# VPAC0_PAR_VPAC_VISS0_S_VBUSP_VISS_FCP_CFA_VBUSP_FLEXCFA register map
Vendor: Texas Instruments
Peripheral module from a debugger description file (folder J7ES).
Registers are 32-bit, read-write, reset 0x0 unless marked. A register's access mark holds for its fields unless they carry their own. Offsets are as the file gives them; lines under a group give offsets from that group; [hi:lo] are bit positions; {n}, {i} and the like mark numbered series; 'fields as' and 'values as' point back to an identical list; <NAME> marks a mode.

## VPAC0_PAR_VPAC_VISS0_S_VBUSP_VISS_FCP_CFA_VBUSP_FLEXCFA
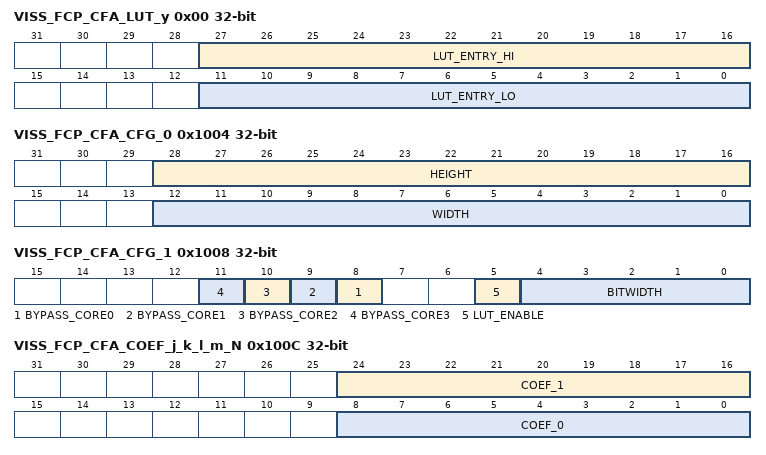
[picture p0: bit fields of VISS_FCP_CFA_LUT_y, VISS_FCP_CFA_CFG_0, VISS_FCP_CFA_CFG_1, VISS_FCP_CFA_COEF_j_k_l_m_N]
0x00 VISS_FCP_CFA_LUT_y — The LUT table contains the information used to reduce the pixle width to 12 from 13-16 Offset = 00088000h + (y * 4h); where y = 0h to 13Fh
  [27:16] LUT_ENTRY_HI — The upper LUT entry n+1.
  [11:0] LUT_ENTRY_LO — The lower LUT entry n+0.
0x1004 VISS_FCP_CFA_CFG_0 — The Control Register controls the input width and height of the module.
  [28:16] HEIGHT — Height of the input image
  [12:0] WIDTH — Width of the input image
0x1008 VISS_FCP_CFA_CFG_1 — The Control Register identifies the bit width of the input image
  [n+8] BYPASS_CORE{n} (n=0..3) — Setting the ~ibypass_core{n} bit will bypass filtering operation, output = input
  [5] LUT_ENABLE
  [4:0] BITWIDTH — BitWidth of the input image, values greater than 16 will be treated as 16 and values less than 12 will be treated as 12.
0x100C VISS_FCP_CFA_COEF_j_k_l_m_N — Coefficients for a=core, b=dir, c=phase, d=row, column=e*2+1 and e*2 Offset = 0008900Ch + (j * 360h) + (k * 120h) + (l * 48h) + (m * Ch) + (n * 4h); where j = 0h to 3h, k = 0h to 2h, l = 0h to 3h, m = 0h to 5h, n = 0h to 2h
  [24:16] COEF_1 — Coefficient - e*2+1
  [8:0] COEF_0 — Coefficient - e*2
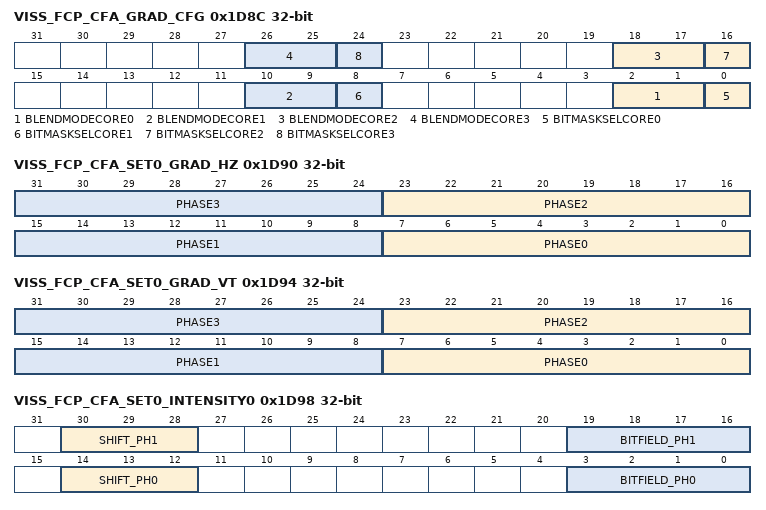
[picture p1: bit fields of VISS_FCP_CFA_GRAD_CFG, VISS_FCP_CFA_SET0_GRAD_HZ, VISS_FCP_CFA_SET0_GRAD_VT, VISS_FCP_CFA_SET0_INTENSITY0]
0x1D8C VISS_FCP_CFA_GRAD_CFG — Gradient configuration for all 4 cores
  [8n+2:8n+1] BLENDMODECORE{n} (n=0..3) — Core-{n} Blend (
  [8n] BITMASKSELCORE{n} (n=0..3) — Core-{n} Bitmask Select (
0x1D90 VISS_FCP_CFA_SET0_GRAD_HZ — Gradient Bitfield selector, Set-0 for Horizontal
  [8n+7:8n] PHASE{n} (n=0..3) — Bitfield selector for Phase-{n}
0x1D94 VISS_FCP_CFA_SET0_GRAD_VT — Gradient Bitfield selector, Set-0 for Vertical
  [8n+7:8n] PHASE{n} (n=0..3) — Bitfield selector for Phase-{n}
0x1D98 VISS_FCP_CFA_SET0_INTENSITY0 — Intensity Bitfield selector and shift for phase0/1
  [30:28] SHIFT_PH1 — Intensity shift for Phase-1
  [19:16] BITFIELD_PH1 — Intensity Bitfield selector for Phase-1
  [14:12] SHIFT_PH0 — Intensity shift for Phase-0
  [3:0] BITFIELD_PH0 — Intensity Bitfield selector for Phase-0
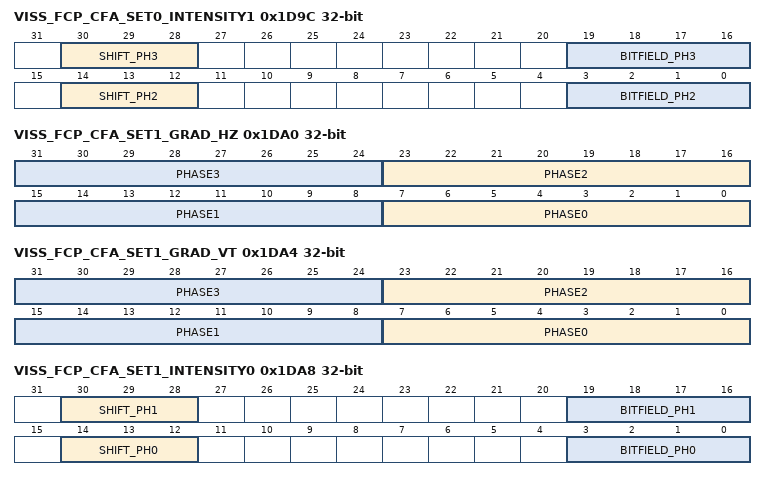
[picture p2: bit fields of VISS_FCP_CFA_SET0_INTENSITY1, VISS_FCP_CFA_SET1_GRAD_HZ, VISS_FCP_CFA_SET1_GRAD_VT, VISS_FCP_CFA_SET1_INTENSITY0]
0x1D9C VISS_FCP_CFA_SET0_INTENSITY1 — Intensity Bitfield selector and shift for phase2/3
  [30:28] SHIFT_PH3 — Intensity shift for Phase-3
  [19:16] BITFIELD_PH3 — Intensity Bitfield selector for Phase-3
  [14:12] SHIFT_PH2 — Intensity shift for Phase-2
  [3:0] BITFIELD_PH2 — Intensity Bitfield selector for Phase-2
0x1DA0 VISS_FCP_CFA_SET1_GRAD_HZ — Gradient Bitfield selector, Set-1 for Horizontal
  [8n+7:8n] PHASE{n} (n=0..3) — Bitfield selector for Phase-{n}
0x1DA4 VISS_FCP_CFA_SET1_GRAD_VT — Gradient Bitfield selector, Set-1 for Vertical
  [8n+7:8n] PHASE{n} (n=0..3) — Bitfield selector for Phase-{n}
0x1DA8 VISS_FCP_CFA_SET1_INTENSITY0 — Intensity Bitfield selector and shift for phase0/1
  fields as VISS_FCP_CFA_SET0_INTENSITY0
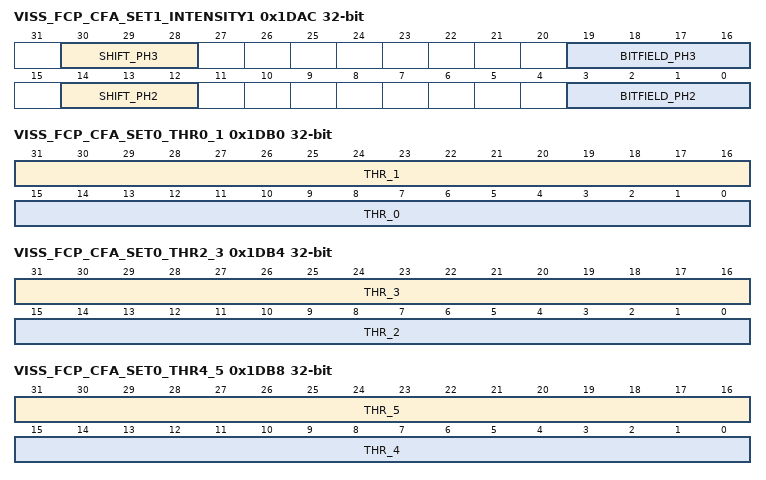
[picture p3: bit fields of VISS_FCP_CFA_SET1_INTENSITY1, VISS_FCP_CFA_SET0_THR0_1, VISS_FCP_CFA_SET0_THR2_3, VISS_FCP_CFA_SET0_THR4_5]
0x1DAC VISS_FCP_CFA_SET1_INTENSITY1 — Intensity Bitfield selector and shift for phase2/3
  fields as VISS_FCP_CFA_SET0_INTENSITY1
0x1DB0 VISS_FCP_CFA_SET0_THR0_1 — Set0 Thr0_1 for H/V Grad difference
  [31:16] THR_1 — H/V Grad diff Threshold_1
  [15:0] THR_0 — H/V Grad diff Threshold_0
0x1DB4 VISS_FCP_CFA_SET0_THR2_3 — Set0 Thr2_3 for H/V Grad difference
  [31:16] THR_3 — H/V Grad diff Threshold_3
  [15:0] THR_2 — H/V Grad diff Threshold_2
0x1DB8 VISS_FCP_CFA_SET0_THR4_5 — Set0 Thr4_5 for H/V Grad difference
  [31:16] THR_5 — H/V Grad diff Threshold_5
  [15:0] THR_4 — H/V Grad diff Threshold_4
0x1DBC VISS_FCP_CFA_SET0_THR6 — Set0 Thr6 for H/V Grad difference
  [15:0] THR_6 — H/V Grad diff Threshold_6
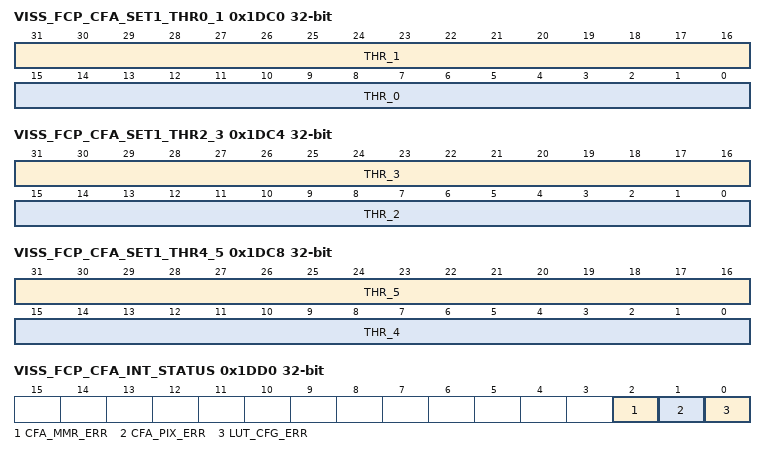
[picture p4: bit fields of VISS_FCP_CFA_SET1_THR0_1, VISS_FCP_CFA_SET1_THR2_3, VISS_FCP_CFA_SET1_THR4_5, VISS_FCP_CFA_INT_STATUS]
0x1DC0 VISS_FCP_CFA_SET1_THR0_1 — Set1 Thr0_1 for H/V Grad difference
  fields as VISS_FCP_CFA_SET0_THR0_1
0x1DC4 VISS_FCP_CFA_SET1_THR2_3 — Set1 Thr2_3 for H/V Grad difference
  fields as VISS_FCP_CFA_SET0_THR2_3
0x1DC8 VISS_FCP_CFA_SET1_THR4_5 — Set1 Thr4_5 for H/V Grad difference
  fields as VISS_FCP_CFA_SET0_THR4_5
0x1DCC VISS_FCP_CFA_SET1_THR6 — Set1 Thr6 for H/V Grad difference
  [15:0] THR_6 — H/V Grad diff Threshold_6
0x1DD0 VISS_FCP_CFA_INT_STATUS access not given — Status/clear register for flexcfa interrupts
  [2] CFA_MMR_ERR — status/clear for error writes to the FIR Filter MMRs during active frame causing potential frame corruption. (access RW1C)
  [1] CFA_PIX_ERR — status/clear for error on line array, set when software accesses pixel array during active frame causing potential frame corruption. (access RW1C)
  [0] LUT_CFG_ERR — status/clear for error on LUT cfg, set when software accesses LUT during active frame causing potential frame corruption. (access RW1C)
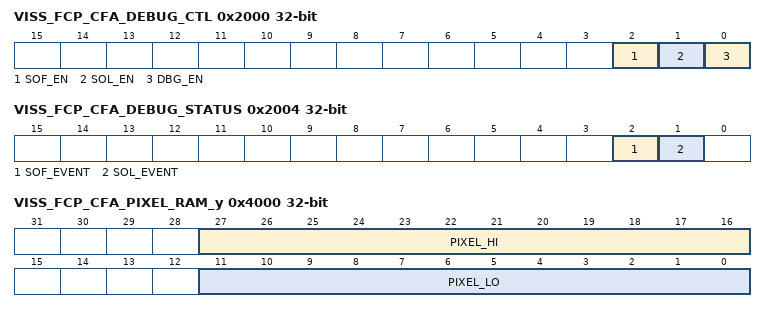
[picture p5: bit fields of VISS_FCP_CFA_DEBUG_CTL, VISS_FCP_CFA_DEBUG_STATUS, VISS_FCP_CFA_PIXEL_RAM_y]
0x2000 VISS_FCP_CFA_DEBUG_CTL — Enable for different debug events
  [2] SOF_EN — Enable for sof event
  [1] SOL_EN — Enable for sol event
  [0] DBG_EN — Enable debug features, set to '0' to disable all debug events
0x2004 VISS_FCP_CFA_DEBUG_STATUS access not given — Set/Clear for debug events
  [2] SOF_EVENT — Status/Clear for sof event, write '1' to clear (access RW1C)
  [1] SOL_EVENT — Status/Clear for sol event, write '1' to clear (access RW1C)
0x2008 VISS_FCP_CFA_LINE_SEL — Selector for which line memory is read or written
  [2:0] LINE_SELECTOR — Selects which line is read or written from the line memory array.
0x4000 VISS_FCP_CFA_PIXEL_RAM_y — The pixel RAM contains the array of 12 bit pixels stored and used by the CFA logic. Pixels are 16 bit aligned. Pixels can only be written two at a time. Offset = 0008C000h + (y * 4h); where y = 0h to 7FFh
  [27:16] PIXEL_HI — The 12 bit pixel data for the selected line upper pixel 'n+1'
  [11:0] PIXEL_LO — The 12 bit pixel data for the selected line lower pixel 'n'
